# G32F031 register map
File version: 1.0
CPU: CM0PLUS r0p1, little endian, no MPU, no FPU, 2 interrupt priority bits
Registers are 32-bit, read-write, reset 0x0 unless marked. A register's access mark holds for its fields unless they carry their own. Offsets are from the block's base; [hi:lo] are bit positions.

## SCU — System Control Unit
Base 0x40000400
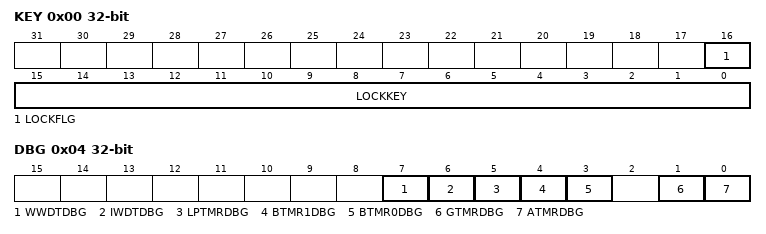
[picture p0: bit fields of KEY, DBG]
0x00 KEY access per field — Read-Write Protection Register
  [16] LOCKFLG ro — Lock flag
  [15:0] LOCKKEY wo — Counter enable
0x04 DBG — System DBG Control Register
  [7] WWDTDBG — In DEBUG mode, WWDT counting method
  [6] IWDTDBG — In DEBUG mode, IWDT counting method
  [5] LPTMRDBG — In DEBUG mode, LPTMR counting method
  [4] BTMR1DBG — In DEBUG mode, BTMR1 counting method
  [3] BTMR0DBG — In DEBUG mode, BTMR0 counting method
  [1] GTMRDBG — In DEBUG mode, GTMR counting method
  [0] ATMRDBG — In DEBUG mode, ATMR counting method

## SPI — Serial peripheral interface
Base 0x40003000
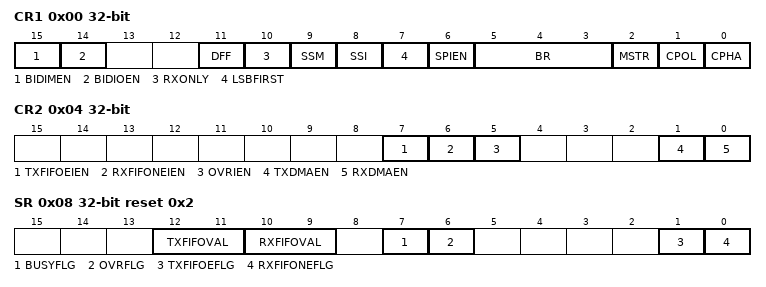
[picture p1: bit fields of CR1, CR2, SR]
0x00 CR1 — control register 1
  [15] BIDIMEN — Bidirectional data mode enable
  [14] BIDIOEN — Output enable in bidirectional mode
  [11] DFF — Data frame format
  [10] RXONLY — Receive only
  [9] SSM — Software slave management
  [8] SSI — Internal slave select
  [7] LSBFIRST — Frame format
  [6] SPIEN — SPI enable
  [5:3] BR — Baud rate control
  [2] MSTR — Master selection
  [1] CPOL — Clock polarity
  [0] CPHA — Clock phase
0x04 CR2 — control register 2
  [7] TXFIFOEIEN — Tx buffer empty interrupt enable
  [6] RXFIFONEIEN — RX buffer not empty interrupt enable
  [5] OVRIEN — Error interrupt enable
  [1] TXDMAEN — Tx buffer DMA enable
  [0] RXDMAEN — Rx buffer DMA enable
0x08 SR ro reset 0x2 — status register
  [12:11] TXFIFOVAL — Transmit FIFO Threshold
  [10:9] RXFIFOVAL — Receive FIFO Threshold
  [7] BUSYFLG — Busy flag
  [6] OVRFLG — Overrun flag
  [1] TXFIFOEFLG — Transmit buffer empty
  [0] RXFIFONEFLG — Receive buffer not empty
0x0C DR — data register
  [15:0] DATA

## UART — Universal asynchronous receiver transmitter
Base 0x40003C00
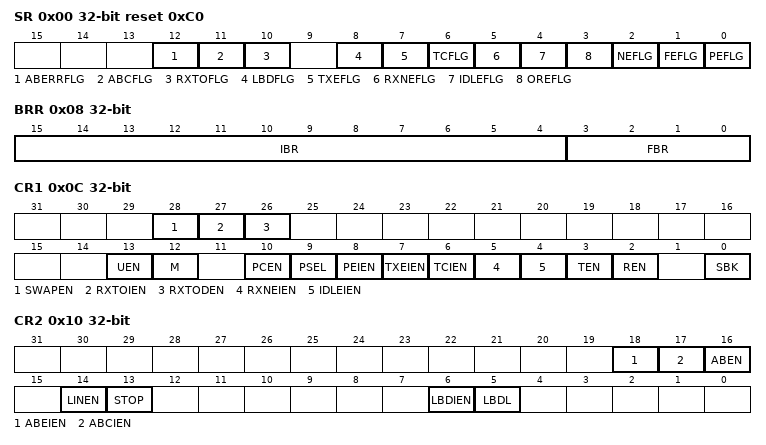
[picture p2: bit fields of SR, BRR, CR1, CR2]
0x00 SR access per field reset 0xC0
  [12] ABERRFLG rw — Auto BR error flag
  [11] ABCFLG rw — Auto BR complete flag
  [10] RXTOFLG rw — RX timeout flag
  [8] LBDFLG rw — LIN break detection flag
  [7] TXEFLG ro — Transmit data register empty
  [6] TCFLG rw — Transmission complete
  [5] RXNEFLG rw — Read data register not empty
  [4] IDLEFLG ro — IDLE line detected
  [3] OREFLG ro — Overrun error
  [2] NEFLG ro — Noise error flag
  [1] FEFLG ro — Framing error
  [0] PEFLG ro — Parity error
0x04 DR
  [8:0] DATA — Data value
0x08 BRR
  [15:4] IBR — Integer baud rate
  [3:0] FBR — Fractional baud rate
0x0C CR1
  [28] SWAPEN — Swap TX/RX Pins Function Enable
  [27] RXTOIEN — Receiver Timeout Interrupt Enable
  [26] RXTODEN — Receive Timeout Detection Function Enable
  [13] UEN — USART enable
  [12] M — Word length
  [10] PCEN — Parity control enable
  [9] PSEL — Parity selection
  [8] PEIEN — PE interrupt enable
  [7] TXEIEN — TXE interrupt enable
  [6] TCIEN — Transmission complete interrupt enable
  [5] RXNEIEN — RXNE interrupt enable
  [4] IDLEIEN — IDLE interrupt enable
  [3] TEN — Transmitter enable
  [2] REN — Receiver enable
  [0] SBK — Send break
0x10 CR2
  [18] ABEIEN — Auto baud error interrupt enable
  [17] ABCIEN — Auto baud complete interrupt enable
  [16] ABEN — Auto baud enable
  [14] LINEN — LIN mode enable
  [13] STOP — STOP bits
  [6] LBDIEN — LIN break detection interrupt enable
  [5] LBDL — LIN break detection length
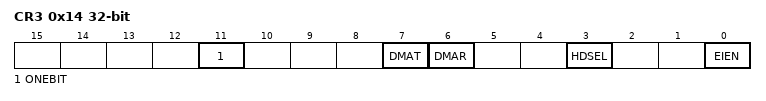
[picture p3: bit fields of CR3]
0x14 CR3
  [11] ONEBIT — Receive data sample mode
  [7] DMAT — DMA enable transmitter
  [6] DMAR — DMA enable receiver
  [3] HDSEL — Half-duplex selection
  [0] EIEN — Error interrupt enable
0x1C RXTOR
  [23:0] RXTO — Receiver Timeout Value Setup

## USART — Universal asynchronous receiver transmitter
Base 0x40003800
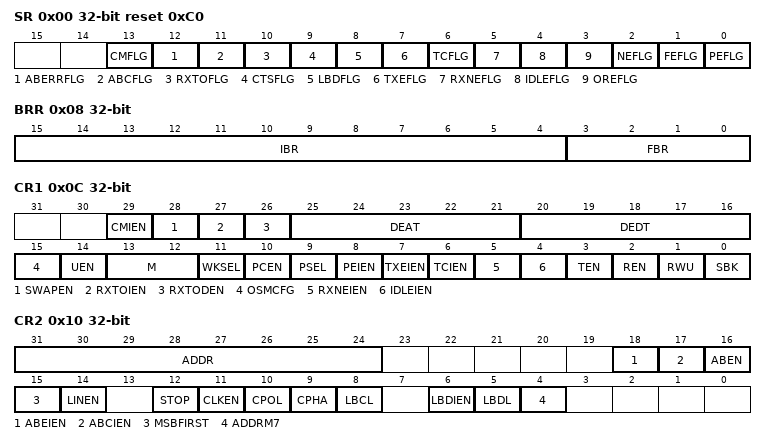
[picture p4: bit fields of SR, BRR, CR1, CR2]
0x00 SR access per field reset 0xC0
  [13] CMFLG rw — character matching flag
  [12] ABERRFLG rw — Auto BR error flag
  [11] ABCFLG rw — Auto BR complete flag
  [10] RXTOFLG rw — RX timeout flag
  [9] CTSFLG rw — CTS flag
  [8] LBDFLG rw — LIN break detection flag
  [7] TXEFLG ro — Transmit data register empty
  [6] TCFLG rw — Transmission complete
  [5] RXNEFLG rw — Read data register not empty
  [4] IDLEFLG ro — IDLE line detected
  [3] OREFLG ro — Overrun error
  [2] NEFLG ro — Noise error flag
  [1] FEFLG ro — Framing error
  [0] PEFLG ro — Parity error
0x04 DR
  [8:0] DATA — Data value
0x08 BRR
  [15:4] IBR — Integer baud rate
  [3:0] FBR — Fractional baud rate
0x0C CR1
  [29] CMIEN — Character match interrupt enable
  [28] SWAPEN — Swap TX/RX Pins Function Enable
  [27] RXTOIEN — Receiver Timeout Interrupt Enable
  [26] RXTODEN — Receive Timeout Detection Function Enable
  [25:21] DEAT — Driver enable assertion time
  [20:16] DEDT — Driver enable deassertion time
  [15] OSMCFG — Oversampling mode configure
  [14] UEN — USART enable
  [13:12] M — Word length
  [11] WKSEL — Wakeup method
  [10] PCEN — Parity control enable
  [9] PSEL — Parity selection
  [8] PEIEN — PE interrupt enable
  [7] TXEIEN — TXE interrupt enable
  [6] TCIEN — Transmission complete interrupt enable
  [5] RXNEIEN — RXNE interrupt enable
  [4] IDLEIEN — IDLE interrupt enable
  [3] TEN — Transmitter enable
  [2] REN — Receiver enable
  [1] RWU — Receiver wakeup
  [0] SBK — Send break
0x10 CR2
  [31:24] ADDR — Node address
  [18] ABEIEN — Auto baud error interrupt enable
  [17] ABCIEN — Auto baud complete interrupt enable
  [16] ABEN — Auto baud enable
  [15] MSBFIRST — Most significant bit first
  [14] LINEN — LIN mode enable
  [12] STOP — STOP bits
  [11] CLKEN — Clock enable
  [10] CPOL — Clock polarity
  [9] CPHA — Clock phase
  [8] LBCL — Last bit clock pulse
  [6] LBDIEN — LIN break detection interrupt enable
  [5] LBDL — LIN break detection length
  [4] ADDRM7 — Bit select of address measure
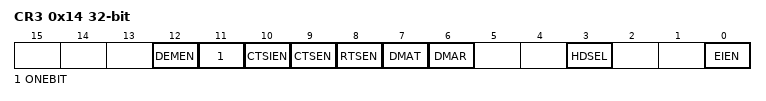
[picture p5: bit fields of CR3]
0x14 CR3
  [12] DEMEN — Driver enable mode
  [11] ONEBIT — Receive data sample mode
  [10] CTSIEN — CTS interrupt enable
  [9] CTSEN — CTS enable
  [8] RTSEN — RTS enable
  [7] DMAT — DMA enable transmitter
  [6] DMAR — DMA enable receiver
  [3] HDSEL — Half-duplex selection
  [0] EIEN — Error interrupt enable
0x1C RXTOR
  [23:0] RXTO — Receiver Timeout Value Setup

## WWDT — Window watchdog
Base 0x40002C00
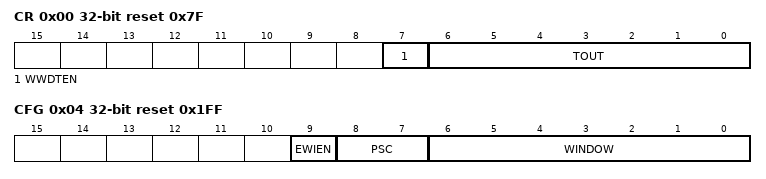
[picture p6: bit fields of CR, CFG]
0x00 CR reset 0x7F — Control register
  [7] WWDTEN — Activation bit
  [6:0] TOUT — 7-bit counter (MSB to LSB)
0x04 CFG reset 0x1FF — Configuration register
  [9] EWIEN — Early wakeup interrupt
  [8:7] PSC — Timer Base Prescaler Factor Configure
  [6:0] WINDOW — 7-bit window value
0x08 SR — Status register
  [0] EWIFLG — Early wakeup interrupt flag
